VERSION ""

NS_ :

BS_:

BU_:

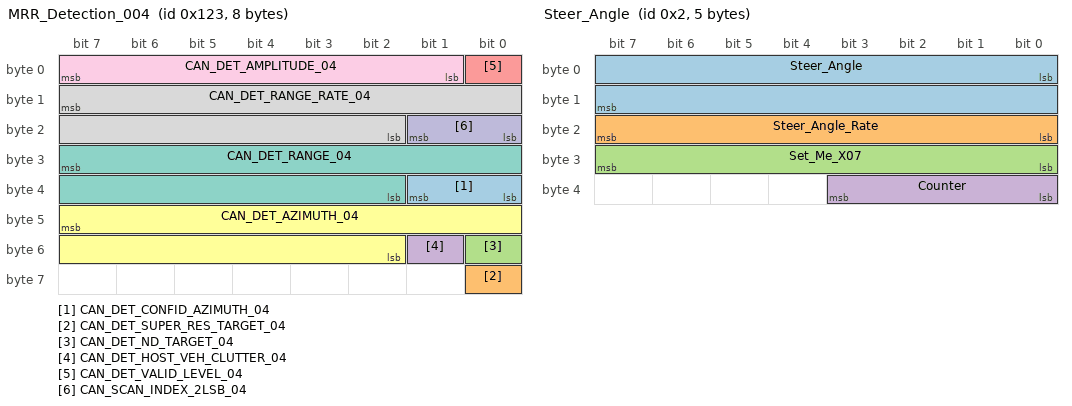
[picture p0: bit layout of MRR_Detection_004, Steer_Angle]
BO_ 291 MRR_Detection_004: 8 MRR
   SG_ CAN_DET_CONFID_AZIMUTH_04 : 33|2@0+ (1,0) [0|3] "" IFV_VFP
   SG_ CAN_DET_SUPER_RES_TARGET_04 : 56|1@0+ (1,0) [0|1] "" IFV_VFP
   SG_ CAN_DET_ND_TARGET_04 : 48|1@0+ (1,0) [0|1] "" IFV_VFP
   SG_ CAN_DET_HOST_VEH_CLUTTER_04 : 49|1@0+ (1,0) [0|1] "" IFV_VFP
   SG_ CAN_DET_VALID_LEVEL_04 : 0|1@0+ (1,0) [0|1] "" IFV_VFP
   SG_ CAN_DET_AZIMUTH_04 : 47|14@0+ (0.0003834,-3.1416) [-3.1416|3.13964] "rad" IFV_VFP
   SG_ CAN_DET_RANGE_04 : 31|14@0+ (0.015625,0) [0|255.984] "m" IFV_VFP
   SG_ CAN_DET_RANGE_RATE_04 : 15|14@0+ (0.015625,-128) [-128|127.984] "m/s" IFV_VFP
   SG_ CAN_DET_AMPLITUDE_04 : 7|7@0+ (1,-64) [-64|63] "dBsm" IFV_VFP
   SG_ CAN_SCAN_INDEX_2LSB_04 : 17|2@0+ (1,0) [0|3] "" IFV_VFP

BO_ 2 Steer_Angle: 5 Vector__XXX

	SG_ Steer_Angle : 0|16@1- (-0.1,0) [0|65535] "" Vector__XXX

	SG_ Steer_Angle_Rate : 16|8@1+ (1,0) [0|255] "" Vector__XXX

	SG_ Set_Me_X07 : 24|8@1+ (1,0) [0|255] "" Vector__XXX

	SG_ Counter : 32|4@1+ (1,0) [0|15] "" Vector__XXX

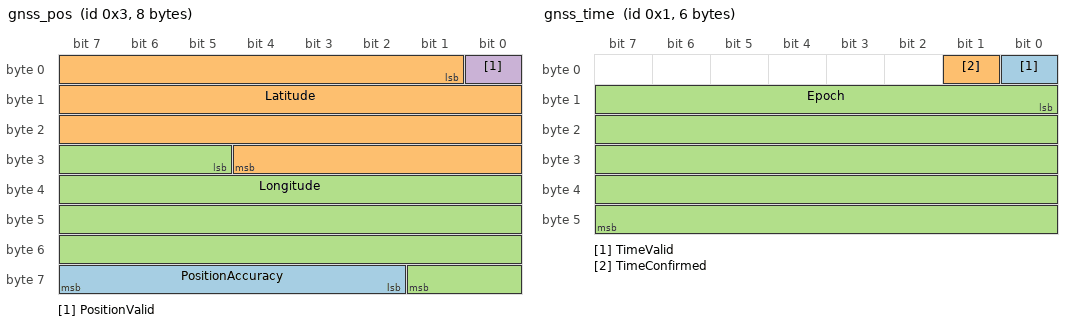
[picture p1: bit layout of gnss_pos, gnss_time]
BO_ 3 gnss_pos: 8 Vector__XXX

	SG_ PositionAccuracy : 58|6@1+ (1,0) [0|63] "m" Vector__XXX

	SG_ Latitude : 1|28@1+ (1e-06,-90) [-90|90] "deg" Vector__XXX

	SG_ Longitude : 29|29@1+ (1e-06,-180) [-180|180] "deg" Vector__XXX

	SG_ PositionValid : 0|1@1+ (1,0) [0|1] "" Vector__XXX

BO_ 1 gnss_time: 6 Vector__XXX

	SG_ TimeValid : 0|1@1+ (1,0) [0|1] "" Vector__XXX

	SG_ TimeConfirmed : 1|1@1+ (1,0) [0|1] "" Vector__XXX

	SG_ Epoch : 8|40@1+ (0.001,1577840400) [1577840400|2677352027] "sec" Vector__XXX

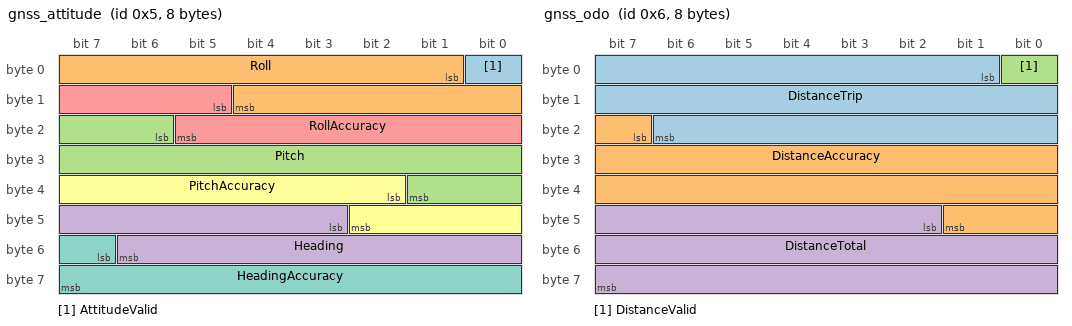
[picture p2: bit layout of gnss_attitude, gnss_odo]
BO_ 5 gnss_attitude: 8 Vector__XXX

	SG_ AttitudeValid : 0|1@1+ (1,0) [0|1] "" Vector__XXX

	SG_ Roll : 1|12@1+ (0.1,-180) [-180|180] "deg" Vector__XXX

	SG_ Pitch : 22|12@1+ (0.1,-90) [-90|90] "deg" Vector__XXX

	SG_ Heading : 43|12@1+ (0.1,0) [0|360] "deg" Vector__XXX

	SG_ RollAccuracy : 13|9@1+ (0.1,0) [0|50] "deg" Vector__XXX

	SG_ PitchAccuracy : 34|9@1+ (0.1,0) [0|50] "deg" Vector__XXX

	SG_ HeadingAccuracy : 55|9@1+ (0.1,0) [0|50] "deg" Vector__XXX

BO_ 6 gnss_odo: 8 Vector__XXX

	SG_ DistanceTrip : 1|22@1+ (1,0) [0|4194303] "m" Vector__XXX

	SG_ DistanceAccuracy : 23|19@1+ (1,0) [0|524287] "m" Vector__XXX

	SG_ DistanceValid : 0|1@1+ (1,0) [0|1] "" Vector__XXX

	SG_ DistanceTotal : 42|22@1+ (1,0) [0|4194303] "km" Vector__XXX

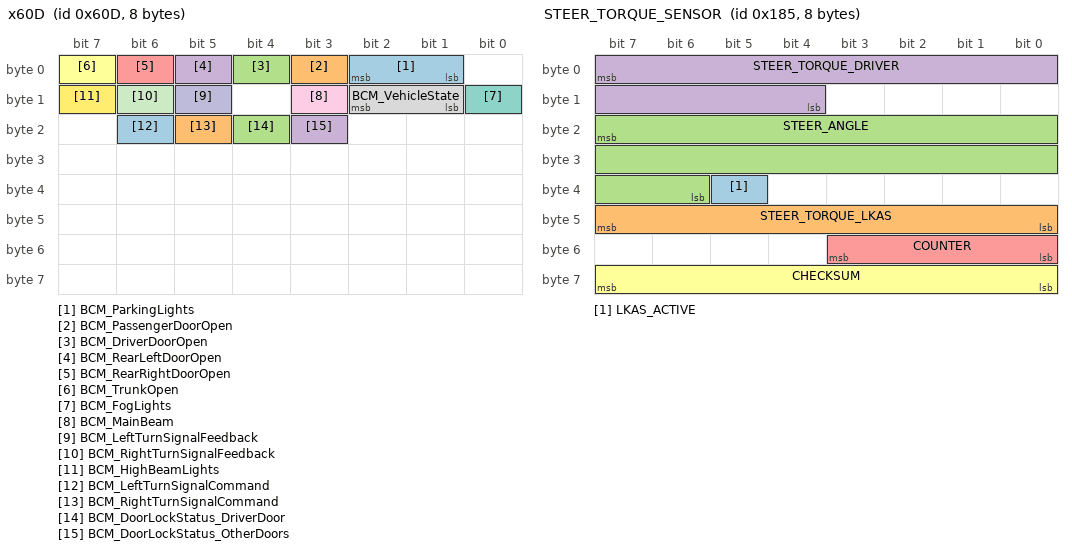
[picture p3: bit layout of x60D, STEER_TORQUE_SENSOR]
BO_ 1549 x60D: 8 Vector__XXX

	SG_ BCM_ParkingLights : 1|2@1+ (1,0) [0|0] "" Vector__XXX

	SG_ BCM_PassengerDoorOpen : 3|1@1+ (1,0) [0|1] "" Vector__XXX

	SG_ BCM_DriverDoorOpen : 4|1@1+ (1,0) [0|1] "" Vector__XXX

	SG_ BCM_RearLeftDoorOpen : 5|1@1+ (1,0) [0|1] "" Vector__XXX

	SG_ BCM_RearRightDoorOpen : 6|1@1+ (1,0) [0|1] "" Vector__XXX

	SG_ BCM_TrunkOpen : 7|1@1+ (1,0) [0|1] "" Vector__XXX

	SG_ BCM_FogLights : 8|1@1+ (1,0) [0|1] "" Vector__XXX

	SG_ BCM_VehicleState : 9|2@1+ (1,0) [0|3] "Enumeration" Vector__XXX

	SG_ BCM_MainBeam : 11|1@1+ (1,0) [0|1] "" Vector__XXX

	SG_ BCM_LeftTurnSignalFeedback : 13|1@1+ (1,0) [0|1] "On/Off" Vector__XXX

	SG_ BCM_RightTurnSignalFeedback : 14|1@1+ (1,0) [0|1] "On/Off" Vector__XXX

	SG_ BCM_HighBeamLights : 15|1@1+ (1,0) [0|1] "" Vector__XXX

	SG_ BCM_LeftTurnSignalCommand : 22|1@1+ (1,0) [0|1] "On/Off" Vector__XXX

	SG_ BCM_RightTurnSignalCommand : 21|1@1+ (1,0) [0|1] "On/Off" Vector__XXX

	SG_ BCM_DoorLockStatus_DriverDoor : 20|1@1+ (1,0) [0|1] "" Vector__XXX

	SG_ BCM_DoorLockStatus_OtherDoors : 19|1@1+ (1,0) [0|1] "" Vector__XXX

BO_ 389 STEER_TORQUE_SENSOR: 8 XXX

	SG_ LKAS_ACTIVE : 37|1@0+ (1,0) [0|3] "" XXX

	SG_ STEER_TORQUE_LKAS : 47|8@0+ (1,0) [0|255] "" XXX

	SG_ STEER_ANGLE : 23|18@0+ (-0.01,1310) [0|262143] "" XXX

	SG_ STEER_TORQUE_DRIVER : 7|12@0+ (-0.01,20.47) [0|4095] "Nm" XXX

	SG_ COUNTER : 51|4@0+ (1,0) [0|15] "" XXX

	SG_ CHECKSUM : 63|8@0+ (1,0) [0|127] "" XXX

BO_ 460 BRAKE_PEDAL: 8 XXX

	SG_ BRAKE_PEDAL : 7|8@0+ (1,0) [0|256] "" XXX

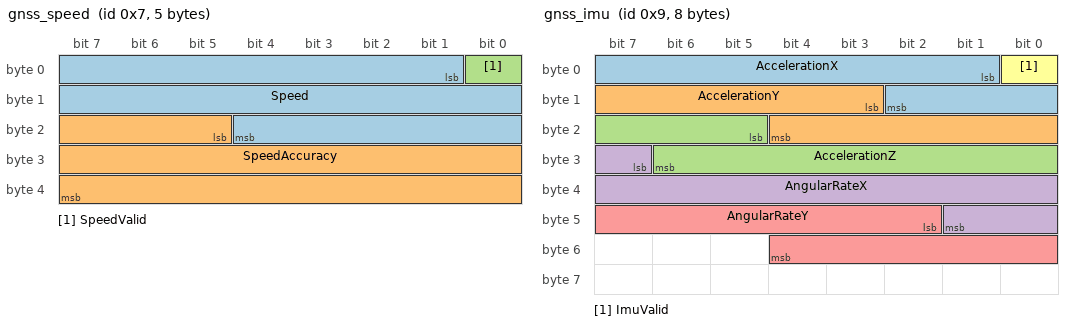
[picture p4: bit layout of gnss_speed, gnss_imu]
BO_ 7 gnss_speed: 5 Vector__XXX

	SG_ Speed : 1|20@1+ (0.001,0) [0|1048.575] "m/s" Vector__XXX

	SG_ SpeedAccuracy : 21|19@1+ (0.001,0) [0|524.287] "m/s" Vector__XXX

	SG_ SpeedValid : 0|1@1+ (1,0) [0|1] "" Vector__XXX

BO_ 9 gnss_imu: 8 Vector__XXX

	SG_ AccelerationX : 1|10@1+ (0.125,-64) [-64|63.875] "m/s^2" Vector__XXX

	SG_ AccelerationY : 11|10@1+ (0.125,-64) [-64|63.875] "m/s^2" Vector__XXX

	SG_ AccelerationZ : 21|10@1+ (0.125,-64) [-64|63.875] "m/s^2" Vector__XXX

	SG_ AngularRateX : 31|11@1+ (0.25,-256) [-256|255.75] "deg/s" Vector__XXX

	SG_ AngularRateY : 42|11@1+ (0.25,-256) [-256|255.75] "deg/s" Vector__XXX

	SG_ ImuValid : 0|1@1+ (1,0) [0|1] "" Vector__XXX

BO_ 644 WHEEL_SPEEDS_FRONT: 8 Vector__XXX

	SG_ WHEEL_SPEED_FR : 7|16@0+ (0.005,0) [0|65535] "KPH" Vector__XXX

	SG_ WHEEL_SPEED_FL : 23|16@0+ (0.005,0) [0|65535] "KPH" Vector__XXX

BO_ 645 WHEEL_SPEEDS_REAR: 8 Vector__XXX

	SG_ WHEEL_SPEED_RR : 7|16@0+ (0.005,0) [0|65535] "KPH" Vector__XXX

	SG_ WHEEL_SPEED_RL : 23|16@0+ (0.005,0) [0|65535] "KPH" Vector__XXX

BO_ 458 Break: 8 Vector__XXX

	SG_ Break_Proc : 7|8@0+ (0.625,0) [0|160] "" Vector__XXX

VAL_ 291 CAN_DET_CONFID_AZIMUTH_04 3 "Low" 2 "Medium_Low" 1 "Medium_High" 0 "High";
